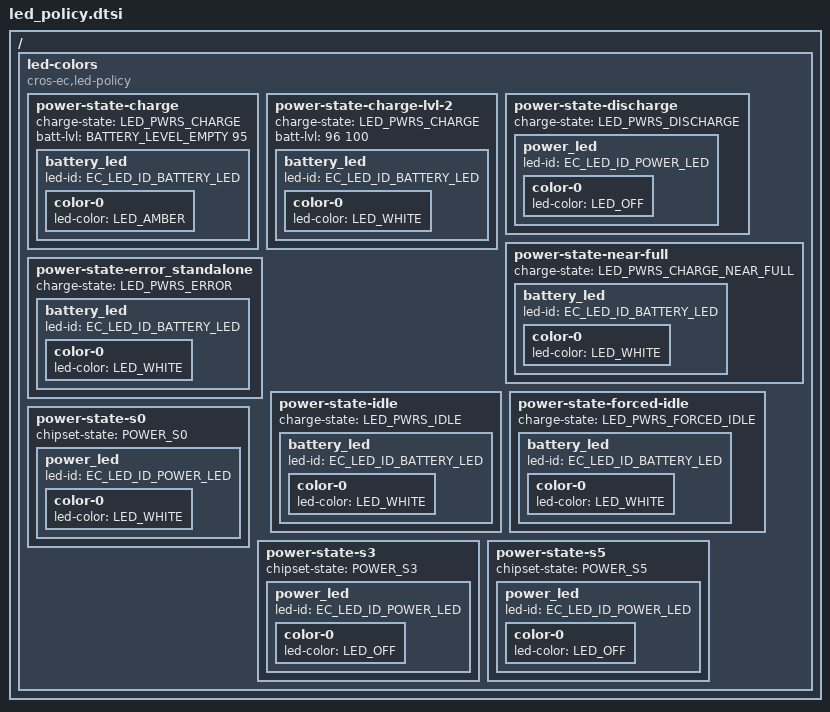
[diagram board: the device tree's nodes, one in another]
#include <dt-bindings/battery.h>

/ {
	led-colors {
		compatible = "cros-ec,led-policy";

		power-state-charge {
			charge-state = "LED_PWRS_CHARGE";
			/* Battery percent range (>= 0, < 96) */
			batt-lvl = <BATTERY_LEVEL_EMPTY 95>;

			battery_led {
				led-id = "EC_LED_ID_BATTERY_LED";
				color-0 {
					led-color = "LED_AMBER";
				};
			};
		};

		power-state-charge-lvl-2 {
			charge-state = "LED_PWRS_CHARGE";
			/* Battery percent range (>= 96%, <= 100%) */
			batt-lvl = <96 100>;

			battery_led {
				led-id = "EC_LED_ID_BATTERY_LED";
				color-0 {
					led-color = "LED_WHITE";
				};
			};
		};

		power-state-discharge {
			charge-state = "LED_PWRS_DISCHARGE";

			power_led {
				led-id = "EC_LED_ID_POWER_LED";
				color-0 {
					led-color = "LED_OFF";
				};
			};
		};

		power-state-near-full {
			charge-state = "LED_PWRS_CHARGE_NEAR_FULL";
			/* Battery percent range (>= 97, <= 100) */
		
			battery_led {
				led-id = "EC_LED_ID_BATTERY_LED";
				color-0 {
					led-color = "LED_WHITE";
				};
			};
		};

		power-state-error_standalone {
			charge-state = "LED_PWRS_ERROR";

			battery_led {
				led-id = "EC_LED_ID_BATTERY_LED";
				color-0 {
					led-color = "LED_WHITE";
				};
			};
		};

		power-state-idle {
			charge-state = "LED_PWRS_IDLE";

			battery_led {
				led-id = "EC_LED_ID_BATTERY_LED";
				color-0 {
					led-color = "LED_WHITE";
				};
			};
		};

		power-state-forced-idle {
			charge-state = "LED_PWRS_FORCED_IDLE";

			battery_led {
				led-id = "EC_LED_ID_BATTERY_LED";
				color-0 {
					led-color = "LED_WHITE";
				};
			};
		};

		power-state-s0 {
			chipset-state = "POWER_S0";

			power_led {
				led-id = "EC_LED_ID_POWER_LED";
				color-0 {
					led-color = "LED_WHITE";
				};
			};
		};

		power-state-s3 {
			chipset-state = "POWER_S3";

			power_led {
				led-id = "EC_LED_ID_POWER_LED";
				color-0 {
					led-color = "LED_OFF";
				};
			};
		};

		power-state-s5 {
			chipset-state = "POWER_S5";

			power_led {
				led-id = "EC_LED_ID_POWER_LED";
				color-0 {
					led-color = "LED_OFF";
				};
			};
		};
	};
};
